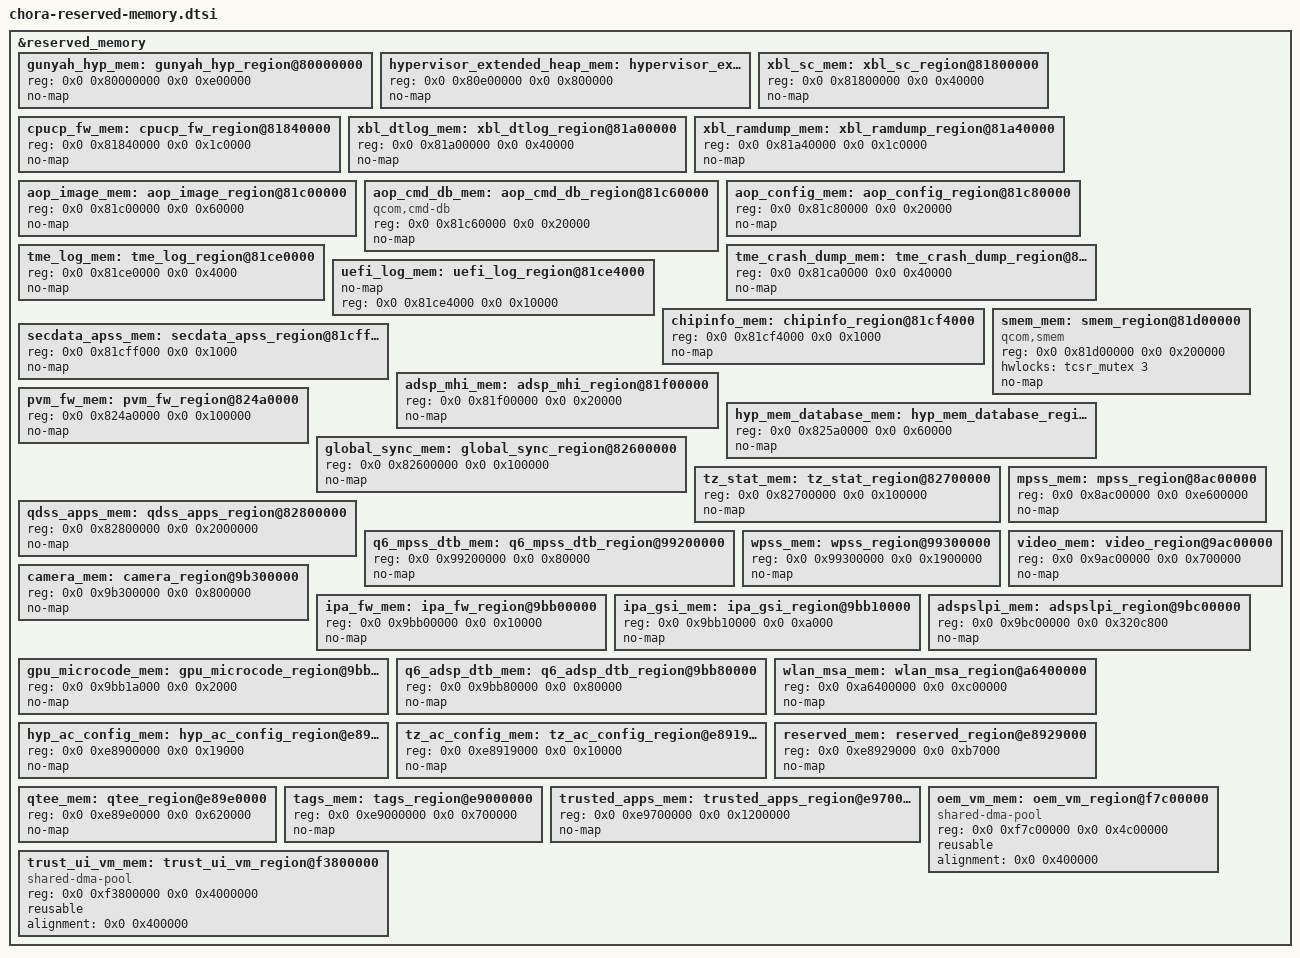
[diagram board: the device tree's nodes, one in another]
// SPDX-License-Identifier: BSD-3-Clause
/*
 * Copyright (c) Qualcomm Technologies, Inc. and/or its subsidiaries.
 */

&reserved_memory {
	#address-cells = <2>;
	#size-cells = <2>;
	ranges;

	gunyah_hyp_mem: gunyah_hyp_region@80000000 {
		reg = <0x0 0x80000000 0x0 0xe00000>;
		no-map;
	};

	hypervisor_extended_heap_mem: hypervisor_extended_heap_region@80e00000 {
		reg = <0x0 0x80e00000 0x0 0x800000>;
		no-map;
	};

	xbl_sc_mem: xbl_sc_region@81800000 {
		reg = <0x0 0x81800000 0x0 0x40000>;
		no-map;
	};

	cpucp_fw_mem: cpucp_fw_region@81840000 {
		reg = <0x0 0x81840000 0x0 0x1c0000>;
		no-map;
	};

	xbl_dtlog_mem: xbl_dtlog_region@81a00000 {
		reg = <0x0 0x81a00000 0x0 0x40000>;
		no-map;
	};

	xbl_ramdump_mem: xbl_ramdump_region@81a40000 {
		reg = <0x0 0x81a40000 0x0 0x1c0000>;
		no-map;
	};

	aop_image_mem: aop_image_region@81c00000 {
		reg = <0x0 0x81c00000 0x0 0x60000>;
		no-map;
	};

	aop_cmd_db_mem: aop_cmd_db_region@81c60000 {
		compatible = "qcom,cmd-db";
		reg = <0x0 0x81c60000 0x0 0x20000>;
		no-map;
	};

	aop_config_mem: aop_config_region@81c80000 {
		reg = <0x0 0x81c80000 0x0 0x20000>;
		no-map;
	};

	tme_crash_dump_mem: tme_crash_dump_region@81ca0000 {
		reg = <0x0 0x81ca0000 0x0 0x40000>;
		no-map;
	};

	tme_log_mem: tme_log_region@81ce0000 {
		reg = <0x0 0x81ce0000 0x0 0x4000>;
		no-map;
	};

	uefi_log_mem: uefi_log_region@81ce4000 {
		no-map;
		reg = <0x0 0x81ce4000 0x0 0x10000>;
	};

	chipinfo_mem: chipinfo_region@81cf4000 {
		reg = <0x0 0x81cf4000 0x0 0x1000>;
		no-map;
	};

	secdata_apss_mem: secdata_apss_region@81cff000 {
		reg = <0x0 0x81cff000 0x0 0x1000>;
		no-map;
	};

	smem_mem: smem_region@81d00000 {
		compatible = "qcom,smem";
		reg = <0x0 0x81d00000 0x0 0x200000>;
		hwlocks = <&tcsr_mutex 3>;
		no-map;
	};

	adsp_mhi_mem: adsp_mhi_region@81f00000 {
		reg = <0x0 0x81f00000 0x0 0x20000>;
		no-map;
	};

	pvm_fw_mem: pvm_fw_region@824a0000 {
		reg = <0x0 0x824a0000 0x0 0x100000>;
		no-map;
	};

	hyp_mem_database_mem: hyp_mem_database_region@825a0000 {
		reg = <0x0 0x825a0000 0x0 0x60000>;
		no-map;
	};

	global_sync_mem: global_sync_region@82600000 {
		reg = <0x0 0x82600000 0x0 0x100000>;
		no-map;
	};

	tz_stat_mem: tz_stat_region@82700000 {
		reg = <0x0 0x82700000 0x0 0x100000>;
		no-map;
	};

	qdss_apps_mem: qdss_apps_region@82800000 {
		reg = <0x0 0x82800000 0x0 0x2000000>;
		no-map;
	};

	mpss_mem: mpss_region@8ac00000 {
		reg = <0x0 0x8ac00000 0x0 0xe600000>;
		no-map;
	};

	q6_mpss_dtb_mem: q6_mpss_dtb_region@99200000 {
		reg = <0x0 0x99200000 0x0 0x80000>;
		no-map;
	};

	wpss_mem: wpss_region@99300000 {
		reg = <0x0 0x99300000 0x0 0x1900000>;
		no-map;
	};

	video_mem: video_region@9ac00000 {
		reg = <0x0 0x9ac00000 0x0 0x700000>;
		no-map;
	};

	camera_mem: camera_region@9b300000 {
		reg = <0x0 0x9b300000 0x0 0x800000>;
		no-map;
	};

	ipa_fw_mem: ipa_fw_region@9bb00000 {
		reg = <0x0 0x9bb00000 0x0 0x10000>;
		no-map;
	};

	ipa_gsi_mem: ipa_gsi_region@9bb10000 {
		reg = <0x0 0x9bb10000 0x0 0xa000>;
		no-map;
	};

	gpu_microcode_mem: gpu_microcode_region@9bb1a000 {
		reg = <0x0 0x9bb1a000 0x0 0x2000>;
		no-map;
	};

	q6_adsp_dtb_mem: q6_adsp_dtb_region@9bb80000 {
		reg = <0x0 0x9bb80000 0x0 0x80000>;
		no-map;
	};

	adspslpi_mem: adspslpi_region@9bc00000 {
		reg = <0x0 0x9bc00000 0x0 0x320c800>;
		no-map;
	};

	wlan_msa_mem: wlan_msa_region@a6400000 {
		reg = <0x0 0xa6400000 0x0 0xc00000>;
		no-map;
	};

	/* UEFI region at 0xa7000000 is reclaimed by Linux */

	/* Linux kernel image is loaded at 0xa8000000 */

	hyp_ac_config_mem: hyp_ac_config_region@e8900000 {
		reg = <0x0 0xe8900000 0x0 0x19000>;
		no-map;
	};

	tz_ac_config_mem: tz_ac_config_region@e8919000 {
		reg = <0x0 0xe8919000 0x0 0x10000>;
		no-map;
	};

	reserved_mem: reserved_region@e8929000 {
		reg = <0x0 0xe8929000 0x0 0xb7000>;
		no-map;
	};

	qtee_mem: qtee_region@e89e0000 {
		reg = <0x0 0xe89e0000 0x0 0x620000>;
		no-map;
	};

	tags_mem: tags_region@e9000000 {
		reg = <0x0 0xe9000000 0x0 0x700000>;
		no-map;
	};

	trusted_apps_mem: trusted_apps_region@e9700000 {
		reg = <0x0 0xe9700000 0x0 0x1200000>;
		no-map;
	};

	trust_ui_vm_mem: trust_ui_vm_region@f3800000 { // VM_KERNEL_MEM
		compatible = "shared-dma-pool";
		reg = <0x0 0xf3800000 0x0 0x4000000>;
		reusable;
		alignment = <0x0 0x400000>;
	};

	oem_vm_mem: oem_vm_region@f7c00000 {
		compatible = "shared-dma-pool";
		reg = <0x0 0xf7c00000 0x0 0x4c00000>;
		reusable;
		alignment = <0x0 0x400000>;
	};

};
